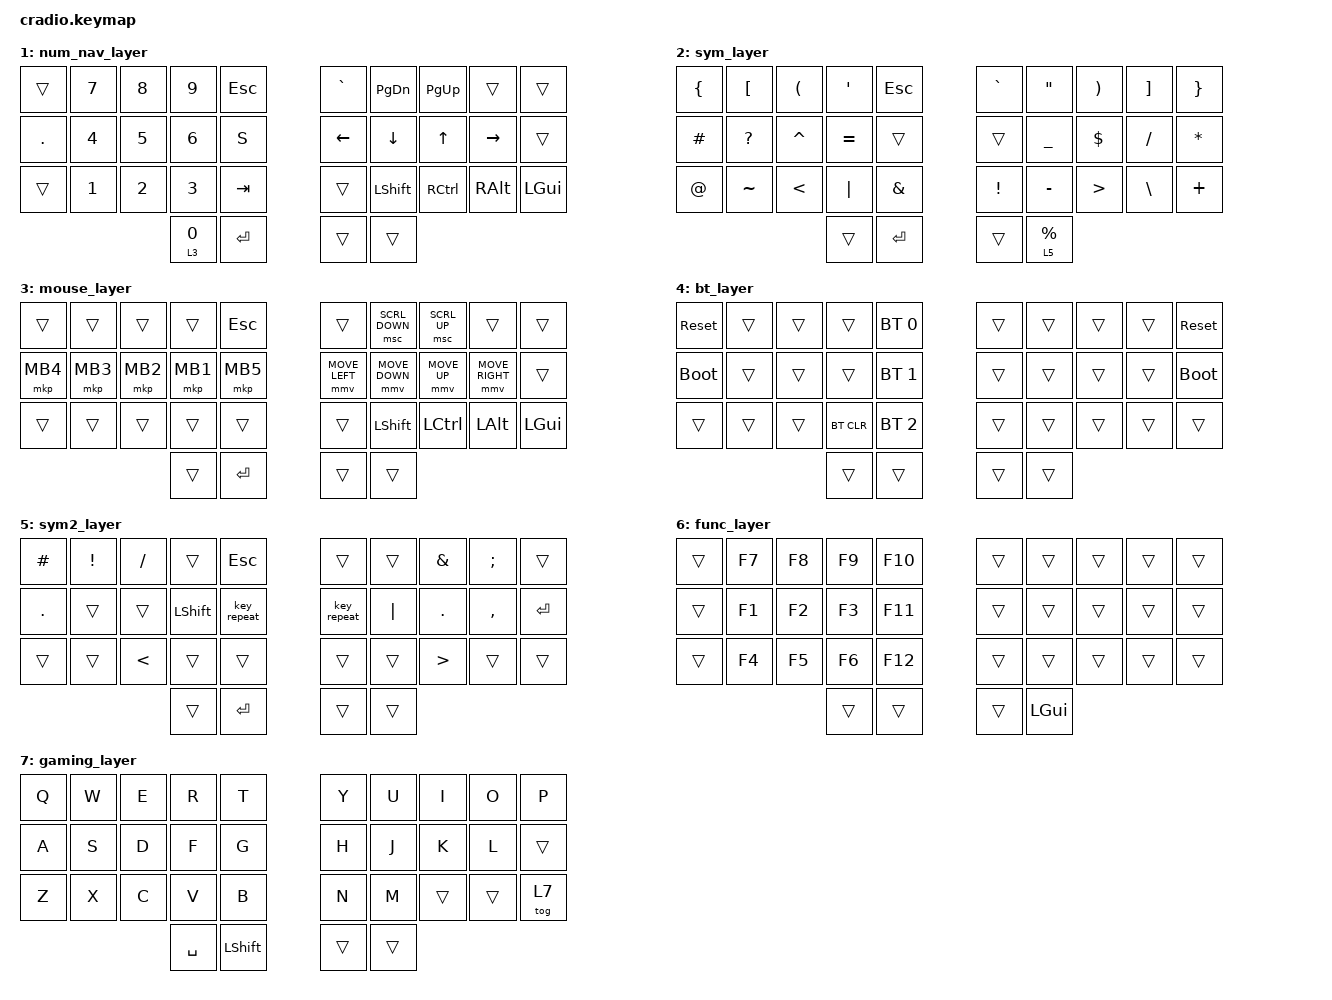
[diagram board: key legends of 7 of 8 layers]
// Copyright (c) 2022 The ZMK Contributors
// SPDX-License-Identifier: MIT

#include <behaviors.dtsi>
#include <dt-bindings/zmk/keys.h>
#include <dt-bindings/zmk/bt.h>
#include <dt-bindings/zmk/pointing.h>

// Home row mods macro
#define HRML(k1,k2,k3,k4) &ht LGUI k1  &ht LALT k2  &ht LCTRL k3  &ht LSHFT k4
#define HRMR(k1,k2,k3,k4) &ht RSHFT k1  &ht RCTRL k2  &ht RALT k3  &ht RGUI k4

/ {
    behaviors {
        ht: hold_tap {
            compatible = "zmk,behavior-hold-tap";
            #binding-cells = <2>;
            flavor = "tap-preferred";
            tapping-term-ms = <220>;
            quick-tap-ms = <150>;
            require-prior-idle-ms = <100>;
            bindings = <&kp>, <&kp>;
        };

        td0: tap_dance_0 {
            compatible = "zmk,behavior-tap-dance";
            #binding-cells = <0>;
            tapping-term-ms = <200>;
            bindings = <&kp BSPC>, <&kp ESC>, <&kp DEL>;
        };


        td1: tap_dance_1 {
            compatible = "zmk,behavior-tap-dance";
            #binding-cells = <0>;
            tapping-term-ms = <200>;
            bindings = <&kp ENTER>, <&kp ESC>;
        };

        td2: tap_dance_2 {
            compatible = "zmk,behavior-tap-dance";
            #binding-cells = <0>;
            tapping-term-ms = <200>;
            bindings = <&kp DOT>, <&kp LS(SEMI)>;
    };

        td3: tap_dance_3 {
            compatible = "zmk,behavior-tap-dance";
            #binding-cells = <0>;
            tapping-term-ms = <200>;
            bindings = <&kp COMMA>, <&kp SEMI>;
        };
    };

/*
    conditional_layers {
        compatible = "zmk,conditional-layers";
        tri_layer {
            if-layers = <2 1>;
            then-layer = <3>;
        };
    };
*/

    keymap {
        compatible = "zmk,keymap";
        default_layer {
            bindings = <
        //╭──────────┬──────────┬──────────┬──────────┬──────────╮   ╭──────────┬──────────┬──────────┬──────────┬────────────╮
            &lt 4 B    &kp L      &kp D      &kp W      &kp Z          &kp GRAVE  &kp F      &kp O      &kp U      &lt 4 J
        //├──────────┼──────────┼──────────┼──────────┼──────────┤   ├──────────┼──────────┼──────────┼──────────┼────────────┤
            HRML(N,     R,         T,         S)        &kp G          &kp Y      HRMR(H,     A,         E,         I)
        //├──────────┼──────────┼──────────┼──────────┼──────────┤   ├──────────┼──────────┼──────────┼──────────┼────────────┤
            &kp Q      &kp X      &kp M      &kp C      &kp V          &kp K      &kp P      &td2       &td3       &lt 6 RALT
        //╰──────────┴──────────┴──────────┼──────────┼──────────┤   ├──────────┼──────────┼──────────┴──────────┴────────────╯
                                             &lt 2 BSPC &kp LSHFT     &key_repeat &lt 1 SPACE
        //                                 ╰──────────┴──────────╯   ╰──────────┴──────────╯
            >;
        };

// 1
        num_nav_layer {
            bindings = <
        //╭────────────┬──────────┬──────────┬──────────┬──────────╮   ╭──────────┬──────────┬──────────┬──────────┬───────────╮
            &trans       &kp N7     &kp N8     &kp N9     &kp ESC        &kp GRAVE  &kp PG_DN  &kp PG_UP  &trans     &trans 
        //├────────────┼──────────┼──────────┼──────────┼──────────┤   ├──────────┼──────────┼──────────┼──────────┼───────────┤
            &kp DOT      &kp N4     &kp N5     &kp N6     &kp S          &kp LEFT   &kp DOWN   &kp UP     &kp RIGHT  &trans 
        //├────────────┼──────────┼──────────┼──────────┼──────────┤   ├──────────┼──────────┼──────────┼──────────┼───────────┤
            &trans       &kp N1     &kp N2     &kp N3     &kp TAB        &trans     &kp LSHFT  &kp RCTRL  &kp RALT   &kp LGUI
        //╰────────────┴──────────┴──────────┼──────────┼──────────┤   ├──────────┼──────────┼──────────┴──────────┴───────────╯
                                               &lt 3 N0   &kp ENTER      &trans     &trans
        //                                   ╰──────────┴──────────╯   ╰──────────┴──────────╯
            >;
        };

//2
        sym_layer {
            bindings = <
        //╭──────────┬──────────┬──────────┬───────────┬──────────╮   ╭───────────┬───────────┬───────────┬──────────┬───────────╮
            &kp LBRC   &kp LBKT   &kp LPAR   &kp SQT     &kp ESC        &kp GRAVE   &kp DQT     &kp RPAR    &kp RBKT   &kp RBRC
        //├──────────┼──────────┼──────────┼───────────┼──────────┤   ├───────────┼───────────┼───────────┼──────────┼───────────┤
            &kp HASH   &kp QMARK  &kp CARET  &kp EQUAL   &trans         &trans      &kp UNDER   &kp DLLR    &kp FSLH   &kp STAR
        //├──────────┼──────────┼──────────┼───────────┼──────────┤   ├───────────┼───────────┼───────────┼──────────┼───────────┤
            &kp AT     &kp TILDE  &kp LT     &kp PIPE    &kp AMPS       &kp EXCL    &kp MINUS   &kp GT      &kp BSLH   &kp PLUS
        //╰──────────┴──────────┴──────────┼───────────┼──────────┤   ├───────────┼───────────┼───────────┴──────────┴───────────╯
                                             &trans      &kp ENTER      &trans      &lt 5 PRCNT
        //                                 ╰───────────┴──────────╯   ╰───────────┴───────────╯
            >;
        };

//3
        mouse_layer {
            bindings = <
        //╭──────────┬──────────┬──────────┬──────────┬──────────╮   ╭────────────────┬────────────────┬──────────────┬─────────────────┬──────────╮
            &trans      &trans     &trans    &trans     &kp ESC        &trans           &msc SCRL_DOWN   &msc SCRL_UP   &trans            &trans
        //├──────────┼──────────┼──────────┼──────────┼──────────┤   ├────────────────┼────────────────┼──────────────┼─────────────────┼──────────┤
            &mkp MB4   &mkp MB3   &mkp MB2   &mkp MB1   &mkp MB5       &mmv MOVE_LEFT   &mmv MOVE_DOWN   &mmv MOVE_UP   &mmv MOVE_RIGHT   &trans
        //├──────────┼──────────┼──────────┼──────────┼──────────┤   ├────────────────┼────────────────┼──────────────┼─────────────────┼──────────┤
            &trans     &trans     &trans     &trans     &trans         &trans           &kp LSHFT        &kp LCTRL      &kp LALT          &kp LGUI
        //╰──────────┴──────────┴──────────┼──────────┼──────────┤   ├────────────────┼────────────────┼──────────────┴─────────────────┴──────────╯
                                             &trans     &kp ENTER      &trans           &trans
        //                                 ╰──────────┴──────────╯   ╰────────────────┴────────────────╯
            >;
        };

//4
        bt_layer {
            bindings = <
        //╭─────────────┬──────────────┬──────────────┬──────────────┬──────────────╮   ╭──────────┬──────────────┬──────────────┬──────────┬───────────╮
            &sys_reset    &trans         &trans         &trans         &bt BT_SEL 0       &trans     &trans         &trans         &trans     &sys_reset
        //├─────────────┼──────────────┼──────────────┼──────────────┼──────────────┤   ├──────────┼──────────────┼──────────────┼──────────┼───────────┤
            &bootloader   &trans         &trans         &trans         &bt BT_SEL 1       &trans     &trans         &trans         &trans    &bootloader
        //├─────────────┼──────────────┼──────────────┼──────────────┼──────────────┤   ├──────────┼──────────────┼──────────────┼──────────┼───────────┤
            &trans        &trans         &trans         &bt BT_CLR     &bt BT_SEL 2       &trans     &trans         &trans         &trans     &trans
        //╰─────────────┴──────────────┴──────────────┼──────────────┼──────────────┤   ├──────────┼──────────────┼──────────────┴──────────┴───────────╯
                                                        &trans         &trans             &trans     &trans
        //                                            ╰──────────────┴──────────────╯   ╰──────────┴──────────╯
            >;
        };

//5
        sym2_layer {
            bindings = <
        //╭──────────┬──────────┬──────────┬───────────┬──────────╮   ╭───────────┬───────────┬───────────┬──────────┬───────────╮
            &kp HASH   &kp EXCL   &kp FSLH   &trans      &kp ESC        &trans      &trans      &kp AMPS    &kp SEMI   &trans  
        //├──────────┼──────────┼──────────┼───────────┼──────────┤   ├───────────┼───────────┼───────────┼──────────┼───────────┤
            &kp DOT    &trans     &trans     &kp LSHFT   &key_repeat   &key_repeat  &kp PIPE    &kp DOT     &kp COMMA  &kp ENTER
        //├──────────┼──────────┼──────────┼───────────┼──────────┤   ├───────────┼───────────┼───────────┼──────────┼───────────┤
            &trans     &trans     &kp LT     &trans      &trans         &trans      &trans      &kp GT      &trans     &trans  
        //╰──────────┴──────────┴──────────┼───────────┼──────────┤   ├───────────┼───────────┼───────────┴──────────┴───────────╯
                                             &trans      &kp ENTER      &trans      &trans   
        //                                 ╰───────────┴──────────╯   ╰───────────┴───────────╯
            >;

        };

//6
        func_layer {
            bindings = <
        //╭─────────────┬──────────────┬──────────────┬──────────────┬──────────────╮   ╭──────────┬──────────────┬──────────────┬──────────┬───────────╮
            &trans        &kp F7         &kp F8         &kp F9         &kp F10            &trans     &trans         &trans         &trans     &trans
        //├─────────────┼──────────────┼──────────────┼──────────────┼──────────────┤   ├──────────┼──────────────┼──────────────┼──────────┼───────────┤
            &trans        &kp F1         &kp F2         &kp F3         &kp F11            &trans     &trans         &trans         &trans      &trans
        //├─────────────┼──────────────┼──────────────┼──────────────┼──────────────┤   ├──────────┼──────────────┼──────────────┼──────────┼───────────┤
            &trans        &kp F4         &kp F5         &kp F6         &kp F12            &trans     &trans         &trans         &trans     &trans
        //╰─────────────┴──────────────┴──────────────┼──────────────┼──────────────┤   ├──────────┼──────────────┼──────────────┴──────────┴───────────╯
                                                        &trans         &trans             &trans     &kp LGUI
        //                                            ╰──────────────┴──────────────╯   ╰──────────┴──────────────╯
            >;
        };

//7
        gaming_layer {
            bindings = <
        //╭─────────────┬──────────────┬──────────────┬──────────────┬──────────────╮   ╭──────────┬──────────────┬──────────────┬──────────┬───────────╮
            &kp Q         &kp W          &kp E          &kp R          &kp T              &kp Y      &kp U          &kp I          &kp O      &kp P
        //├─────────────┼──────────────┼──────────────┼──────────────┼──────────────┤   ├──────────┼──────────────┼──────────────┼──────────┼───────────┤
            &kp A         &kp S          &kp D          &kp F          &kp G              &kp H      &kp J          &kp K          &kp L      &trans
        //├─────────────┼──────────────┼──────────────┼──────────────┼──────────────┤   ├──────────┼──────────────┼──────────────┼──────────┼───────────┤
            &kp Z         &kp X          &kp C          &kp V          &kp B              &kp N      &kp M          &trans         &trans     &tog 7
        //╰─────────────┴──────────────┴──────────────┼──────────────┼──────────────┤   ├──────────┼──────────────┼──────────────┴──────────┴───────────╯
                                                        &kp SPACE      &kp LSHFT          &trans     &trans
        //                                            ╰──────────────┴──────────────╯   ╰──────────┴──────────────╯
            >;
        };
    };
};
